VERSION ""

NS_ :

BS_:

BU_: MeterEcu EngineEcu AbsEcu KeyFobEcu DiagTool

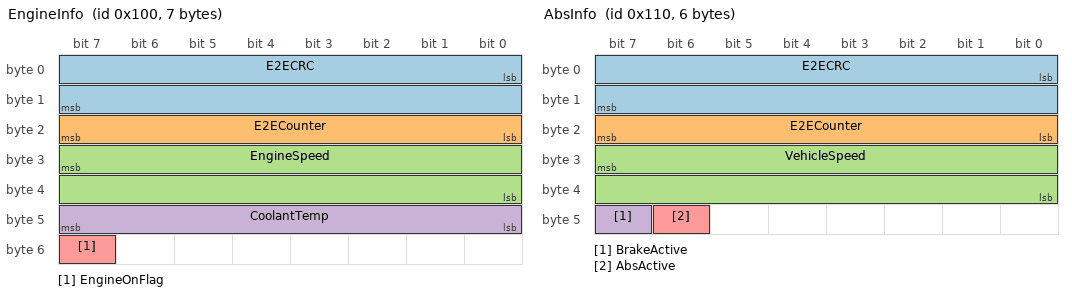
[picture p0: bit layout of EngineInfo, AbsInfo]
BO_ 256 EngineInfo: 7 EngineEcu
 SG_ E2ECRC       : 0|16@1+  (1,0)    [0|65535]  ""     MeterEcu
 SG_ E2ECounter   : 23|8@0+  (1,0)    [0|255]    ""     MeterEcu
 SG_ EngineSpeed  : 31|16@0+ (1,0)    [0|15000]  "rpm"  MeterEcu
 SG_ CoolantTemp  : 47|8@0+  (1,0)    [0|255]    "degC" MeterEcu
 SG_ EngineOnFlag : 55|1@0+  (1,0)    [0|1]      ""     MeterEcu

BO_ 272 AbsInfo: 6 AbsEcu
 SG_ E2ECRC       : 0|16@1+  (1,0)    [0|65535]  ""     MeterEcu
 SG_ E2ECounter   : 23|8@0+  (1,0)    [0|255]    ""     MeterEcu
 SG_ VehicleSpeed : 31|16@0+ (0.01,0) [0|655.35] "km/h" MeterEcu
 SG_ BrakeActive  : 47|1@0+  (1,0)    [0|1]      ""     MeterEcu
 SG_ AbsActive    : 46|1@0+  (1,0)    [0|1]      ""     MeterEcu

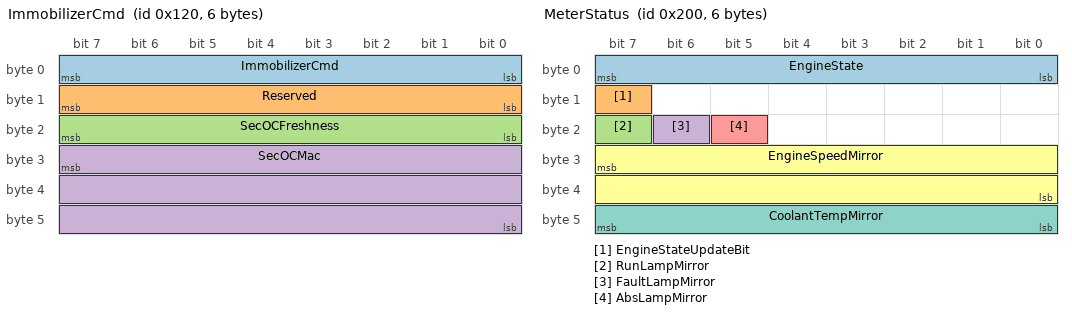
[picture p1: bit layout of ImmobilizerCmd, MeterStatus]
BO_ 288 ImmobilizerCmd: 6 KeyFobEcu
 SG_ ImmobilizerCmd  : 7|8@0+   (1,0) [0|1]        ""  MeterEcu
 SG_ Reserved        : 15|8@0+  (1,0) [0|255]      ""  MeterEcu
 SG_ SecOCFreshness  : 23|8@0+  (1,0) [0|255]      ""  MeterEcu
 SG_ SecOCMac        : 31|24@0+ (1,0) [0|16777215] ""  MeterEcu

BO_ 512 MeterStatus: 6 MeterEcu
 SG_ EngineState          : 7|8@0+   (1,0) [0|3]     ""     DiagTool
 SG_ EngineStateUpdateBit : 15|1@0+  (1,0) [0|1]     ""     DiagTool
 SG_ RunLampMirror        : 23|1@0+  (1,0) [0|1]     ""     DiagTool
 SG_ FaultLampMirror      : 22|1@0+  (1,0) [0|1]     ""     DiagTool
 SG_ AbsLampMirror        : 21|1@0+  (1,0) [0|1]     ""     DiagTool
 SG_ EngineSpeedMirror    : 31|16@0+ (1,0) [0|15000] "rpm"  DiagTool
 SG_ CoolantTempMirror    : 47|8@0+  (1,0) [0|255]   "degC" DiagTool

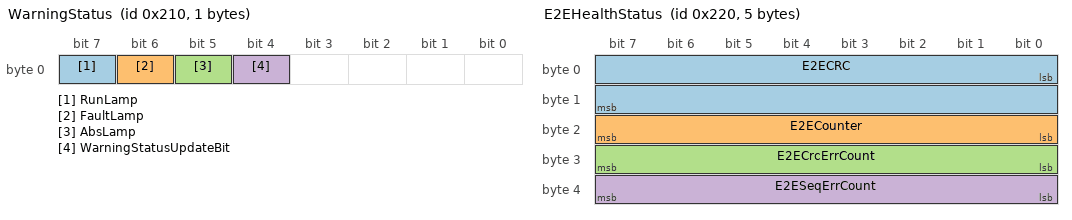
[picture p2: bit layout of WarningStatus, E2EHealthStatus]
BO_ 528 WarningStatus: 1 MeterEcu
 SG_ RunLamp             : 7|1@0+ (1,0) [0|1] "" DiagTool
 SG_ FaultLamp           : 6|1@0+ (1,0) [0|1] "" DiagTool
 SG_ AbsLamp             : 5|1@0+ (1,0) [0|1] "" DiagTool
 SG_ WarningStatusUpdateBit : 4|1@0+ (1,0) [0|1] "" DiagTool

BO_ 544 E2EHealthStatus: 5 MeterEcu
 SG_ E2ECRC         : 0|16@1+ (1,0) [0|65535] "" DiagTool
 SG_ E2ECounter     : 23|8@0+ (1,0) [0|255]   "" DiagTool
 SG_ E2ECrcErrCount : 31|8@0+ (1,0) [0|255]   "" DiagTool
 SG_ E2ESeqErrCount : 39|8@0+ (1,0) [0|255]   "" DiagTool

BO_ 560 ImmobilizerStatus: 1 MeterEcu
 SG_ ImmobilizerStatus : 7|8@0+ (1,0) [0|1] "" DiagTool

BO_ 1024 MeterEcu_Nm: 2 MeterEcu
 SG_ ControlBitVector : 7|8@0+  (1,0) [0|255] "" DiagTool
 SG_ SourceNodeId     : 15|8@0+ (1,0) [0|255] "" DiagTool

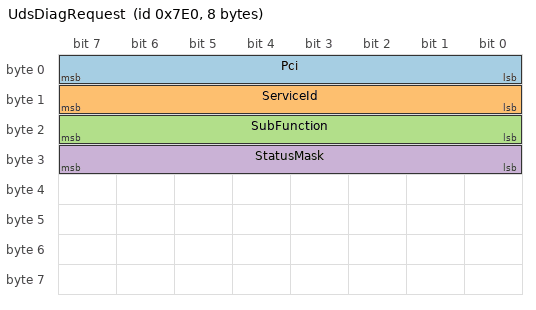
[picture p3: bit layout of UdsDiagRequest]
BO_ 2016 UdsDiagRequest: 8 DiagTool
 SG_ Pci         : 7|8@0+  (1,0) [0|255] "" MeterEcu
 SG_ ServiceId   : 15|8@0+ (1,0) [0|255] "" MeterEcu
 SG_ SubFunction : 23|8@0+ (1,0) [0|255] "" MeterEcu
 SG_ StatusMask  : 31|8@0+ (1,0) [0|255] "" MeterEcu

BO_ 2024 UdsDiagResponse: 8 MeterEcu
 SG_ Pci             : 7|8@0+   (1,0) [0|255]      "" DiagTool
 SG_ ServiceId       : 15|8@0+  (1,0) [0|255]      "" DiagTool
 SG_ SubFuncEcho     : 23|8@0+  (1,0) [0|255]      "" DiagTool
 SG_ StatusAvailMask : 31|8@0+  (1,0) [0|255]      "" DiagTool
 SG_ DtcCode         : 39|24@0+ (1,0) [0|16777215] "" DiagTool
 SG_ DtcCount        : 55|8@0+  (1,0) [0|255]      "" DiagTool
 SG_ DtcStatus       : 63|8@0+  (1,0) [0|255]      "" DiagTool

CM_ BO_ 256  "TX: EngineEcu -> MeterEcu (CAN ID 0x100). エンジン ECU が送信するエンジン情報フレーム。動作確認時はテストツールからこのフレームを送信してエンジン ECU をシミュレートする。AUTOSAR E2E Profile 05 で保護 (byte[0-1]=CRC16 リトルエンディアン, byte[2]=Counter)。";
CM_ BO_ 272  "TX: AbsEcu -> MeterEcu (CAN ID 0x110). ABS ECU が送信する制動情報フレーム。動作確認時はテストツールからこのフレームを送信して ABS ECU をシミュレートする。AUTOSAR E2E Profile 05 で保護 (byte[0-1]=CRC16 リトルエンディアン, byte[2]=Counter)。";
CM_ BO_ 512  "TX: MeterEcu -> (CAN ID 0x200). メータ ECU (Arduino) が送信するエンジン状態フレーム。EngineState が変化したときに送信され、変化がなくても約9秒ごとに周期フロアとして再送される(ComFilterAlgorithm + TxModeMode=MIXED)。byte[2-5] は uds_tester の仮想メータ表示用に WarningStatus/EngineInfo と同値をミラーした本プロジェクト独自の拡張。E2E保護は付与しない。";
CM_ BO_ 528  "TX: MeterEcu -> (CAN ID 0x210). メータ ECU (Arduino) が送信する警告灯状態フレーム。RunLamp/FaultLamp/AbsLamp の3信号を Com_SendSignalGroup() で1つの Signal Group としてまとめてコミットし、いずれかが変化したときに送信される(FAULT点滅中は500msごとに送信)。通常は DIRECT(変化時のみ)、FaultLamp/AbsLamp が点灯している間は TMS により MIXED へ切り替わり約2秒ごとに周期フロアとして再送される。";
CM_ BO_ 288  "TX: KeyFobEcu -> MeterEcu (CAN ID 0x120). イモビライザー解除コマンド。SecOC Profile 1 (24Bit-CMAC-8Bit-FV) で保護 (byte[2]=Freshness 8bit, byte[3-5]=AES-128-CMAC 上位24bit)。検証に成功したフレームだけが Com へ届く。";
CM_ BO_ 544  "TX: MeterEcu -> (CAN ID 0x220). E2EMon (CDD相当モジュール) が発行するネットワーク健全性テレメトリ。EngineInfo/AbsInfo 受信側のE2E検証で検出した累積エラー数 (E2ECrcErrCount=CRC不一致, E2ESeqErrCount=シーケンス異常、それぞれ0-255で飽和、電源投入時0リセット)。Comの PERIODIC送信モードにより6000ms周期で自動送信される(ComTxModeMode=PERIODIC、ASW/CDDは送信タイミングに関与しない)。テレメトリ自体の破損を監視ツールが検出できるようAUTOSAR E2E Profile 05 で保護 (byte[0-1]=CRC16 リトルエンディアン, byte[2]=Counter)。Demの DTC 管理とは独立。";
CM_ BO_ 560  "TX: MeterEcu -> (CAN ID 0x230). Signal Gateway が SecOC 検証済みの ImmobilizerCmd をそのまま転送するフレーム。E2E/SecOC 保護は付与しない。ComTxModeNumberOfRepetitions により変化のたびに約100ms間隔で計3回送信される。";
CM_ BO_ 1024 "TX/RX: MeterEcu <-> 他ノード (CAN ID 0x400). ネットワークマネジメント(NM)フレーム。CanNm が Repeat Message State / Normal Operation State の間、1000msごとに送信して生存を示す。シグナル値ではなくバス上の生存確認が目的のため E2E 保護は付与しない。Com を経由せず CanIf と直接やり取りする。";
CM_ BO_ 2016 "TX: DiagTool -> MeterEcu (CAN ID 0x7E0). UDS 診断要求 (ISO 14229-1 / ISO 15765-2)。リクエストは最大 7 バイトのため常に Single Frame (SF)。Pci=0x0N (N=UDS payload length), ServiceId=SID.";
CM_ BO_ 2024 "TX: MeterEcu -> DiagTool (CAN ID 0x7E8). UDS 診断応答 (ISO 15765-2 CanTp)。Short response (<=7byte): Single Frame (PCI=0x0N)。Long response (>=8byte): First Frame (PCI=0x10 0xNN) + Consecutive Frame (PCI=0x21..)。DBCシグナルはSF時のみ正確にデコードされる。FF/CF時はCANアナライザの生Hexビューで確認すること。";

CM_ SG_ 256 EngineSpeed  "Engine speed [rpm]. STARTING->RUNNING when >= 500. RUNNING->FAULT when < 100.";
CM_ SG_ 256 CoolantTemp  "Coolant temperature [degC]. RUNNING->FAULT when >= 100.";
CM_ SG_ 256 EngineOnFlag "Engine on request. OFF->STARTING when 1. Any state->OFF when 0.";

CM_ SG_ 256 E2ECRC       "AUTOSAR E2E Profile 05 CRC16 (poly=0x1021, init=0xFFFF)。byte[0-1] にリトルエンディアンで格納。Counter, データ, DataID(0x0100: 下位→上位) の順で計算。";
CM_ SG_ 256 E2ECounter   "AUTOSAR E2E Profile 05 8bit カウンタ (0-255 の循環、予約値なし)。";
CM_ SG_ 272 E2ECRC       "AUTOSAR E2E Profile 05 CRC16 (poly=0x1021, init=0xFFFF)。byte[0-1] にリトルエンディアンで格納。Counter, データ, DataID(0x0110: 下位→上位) の順で計算。";
CM_ SG_ 272 E2ECounter   "AUTOSAR E2E Profile 05 8bit カウンタ (0-255 の循環、予約値なし)。";
CM_ SG_ 272 VehicleSpeed "Vehicle speed from ABS ECU [km/h, factor=0.01]. Raw 0x0064 = 1.00 km/h.";
CM_ SG_ 272 BrakeActive  "Brake pedal status. 0=Released, 1=Active.";
CM_ SG_ 272 AbsActive    "ABS system status. 0=Inactive, 1=ABS active. MeterEcu LED turns on when ABS is active (unless ENGINE_FAULT, which blinks with higher priority).";

CM_ SG_ 544 E2ECRC       "AUTOSAR E2E Profile 05 CRC16。byte[0-1] にリトルエンディアンで格納。DataID=0x0220。";
CM_ SG_ 544 E2ECounter   "AUTOSAR E2E Profile 05 8bit カウンタ。";
CM_ SG_ 288 ImmobilizerCmd "0=LOCK / 1=UNLOCK。SecOC 検証後に Com へ渡される。";
CM_ SG_ 288 Reserved       "常に 0x00。0 以外のフレームは Com_RxIpduCallout が棄却する。";
CM_ SG_ 288 SecOCFreshness "SecOC の Freshness Value (8bit 単調増加、切り詰めなし)。同じ値や戻りはリプレイとして拒否される。";
CM_ SG_ 288 SecOCMac       "AES-128-CMAC (DataId(0x0120) | Authentic payload | Freshness) の上位24bit。";
CM_ SG_ 560 ImmobilizerStatus "ImmobilizerCmd と同値 (0=LOCK / 1=UNLOCK)。";
CM_ SG_ 512 EngineState  "Current engine state reported by MeterEcu (on change, plus periodic floor).";
CM_ SG_ 512 EngineStateUpdateBit "1=EngineState の値が変化したために送信、0=周期フロアによる再送。";
CM_ SG_ 512 RunLampMirror    "WarningStatus.RunLamp と同値のミラー (仮想メータ表示用)。";
CM_ SG_ 512 FaultLampMirror  "WarningStatus.FaultLamp と同値のミラー。";
CM_ SG_ 512 AbsLampMirror    "WarningStatus.AbsLamp と同値のミラー。";
CM_ SG_ 512 EngineSpeedMirror "EngineInfo の検証済み EngineSpeed と同値のミラー。";
CM_ SG_ 512 CoolantTempMirror "EngineInfo の検証済み CoolantTemp と同値のミラー。";

CM_ SG_ 528 RunLamp   "RUNNING LED (D6) state, mirrors App_WarningIndicator's local LED output. Part of a Com Signal Group (WarningStatus) committed atomically via Com_SendSignalGroup().";
CM_ SG_ 528 FaultLamp "FAULT LED (D7) state. Blinks at 500ms while ENGINE_STATE_FAULT, so this signal toggles every WarningStatus commit during blinking.";
CM_ SG_ 528 WarningStatusUpdateBit "1=いずれかの警告灯が変化したために送信、0=MIXED の周期フロアによる再送。";
CM_ SG_ 528 AbsLamp   "ABS LED (D8) state, mirrors AbsActive from the ABS ECU (CAN 0x110).";

CM_ SG_ 1024 ControlBitVector "bit0=Repeat Message Request のみ使用 (CanNm_RepeatMessageRequest で Repeat Message State へ入ったときだけ 1)。他のビットは常に 0。";
CM_ SG_ 1024 SourceNodeId     "NM node identifier of the transmitting ECU. 0x01=MeterEcu.";

CM_ SG_ 2016 Pci         "ISO 15765-2 PCI byte. Upper nibble=frame type (0x0=SingleFrame). Lower nibble=UDS payload length (1-7).";
CM_ SG_ 2016 ServiceId   "UDS Service ID (SID). 0x10=DiagnosticSessionControl, 0x11=ECUReset, 0x14=ClearDiagnosticInformation, 0x19=ReadDTCInformation, 0x22=ReadDataByIdentifier, 0x3E=TesterPresent.";
CM_ SG_ 2016 SubFunction "byte[2]. SID 0x19: subFunction (0x01=reportCount / 0x02=reportByMask). SID 0x14: groupOfDTC upper byte (0xFF for all).";
CM_ SG_ 2016 StatusMask  "byte[3]. SID 0x19: statusMask to filter DTCs. bit0=TF, bit2=PDTC, bit3=CDTC, bit4=TNCLC, bit5=TFSLC. Use 0x08 for confirmedDTC only.";
CM_ SG_ 2024 Pci         "ISO 15765-2 PCI byte. SF: 0x0N (lower nibble=UDS length). FF: 0x10 (next byte=total length). CF: 0x2N (N=sequence number).";
CM_ SG_ 2024 ServiceId   "UDS Response SID. Positive = request SID + 0x40. 0x50=SessionCtrl_Pos, 0x51=ECUReset_Pos, 0x54=ClearDTC_Pos, 0x59=ReadDTC_Pos, 0x62=ReadData_Pos, 0x7E=TesterPresent_Pos, 0x7F=NegativeResponse.";
CM_ SG_ 2024 SubFuncEcho     "byte[2]. Echo of request subFunction. 0x01=reportCount / 0x02=reportByMask.";
CM_ SG_ 2024 StatusAvailMask "byte[3]. statusAvailabilityMask: supported status bits (0x3D in this implementation). bit0=TF, bit2=PDTC, bit3=CDTC, bit4=TNCLC, bit5=TFSLC.";
CM_ SG_ 2024 DtcCode         "bytes[4-6] (24-bit). Valid when subFunc=0x02 (reportDTCByStatusMask). 24-bit DTC code. 0x000101=EngineOverheat, 0x000102=EngineStall, 0x000103=SpeedNoFlag, 0x000104=StartingTimeout.";
CM_ SG_ 2024 DtcCount        "byte[6]. Valid when subFunc=0x01 (reportNumberOfDTCByStatusMask). Number of DTCs matching statusMask (low byte).";
CM_ SG_ 2024 DtcStatus       "byte[7]. Valid when subFunc=0x02. DTC status byte. bit0=TF, bit2=PDTC, bit3=CDTC, bit4=TNCLC, bit5=TFSLC. 0x2D=FAILED_current, 0x2C=FAILED_history, 0x10=NotTested.";

 0 "OFF"
 1 "ON" ;

 0 "Released"
 1 "Active" ;

 0 "Inactive"
 1 "Active" ;

 0 "OFF"
 1 "STARTING"
 2 "RUNNING"
 3 "FAULT" ;

 0 "LOCK"
 1 "UNLOCK" ;

 0 "LOCK"
 1 "UNLOCK" ;

 0 "Off"
 1 "On" ;

 0 "Off"
 1 "On" ;

 0 "Off"
 1 "On" ;

 1 "MeterEcu" ;

 16  "DiagnosticSessionControl"
 17  "ECUReset"
 20  "ClearDiagnosticInformation"
 25  "ReadDTCInformation"
 34  "ReadDataByIdentifier"
 62  "TesterPresent" ;

 1   "reportNumberOfDTCByStatusMask"
 2   "reportDTCByStatusMask"
 255 "groupOfDTC_All (0xFF for SID14)" ;

 80  "DiagnosticSessionControl_Pos"
 81  "ECUReset_Pos"
 84  "ClearDiagnosticInformation_Pos"
 89  "ReadDTCInformation_Pos"
 98  "ReadDataByIdentifier_Pos"
 126 "TesterPresent_Pos"
 127 "NegativeResponse" ;

 257 "ENGINE_OVERHEAT"
 258 "ENGINE_STALL"
 259 "ENGINE_SPEED_NO_FLAG"
 260 "ENGINE_STARTING_TIMEOUT" ;

 16  "NotTested_since_clear"
 44  "FAILED_history (PDTC+CDTC+TFSLC)"
 45  "FAILED_current (TF+PDTC+CDTC+TFSLC)" ;
